# TLE985x register map
Vendor: Infineon Technologies AG; File version: 1.3
CPU: CM0 r0p0, little endian, no MPU, no FPU, 2 interrupt priority bits
Registers are 32-bit, read-write, no defined reset value unless marked. A register's access mark holds for its fields unless they carry their own. Offsets are from the block's base; [hi:lo] are bit positions; 'fields as' and 'values as' point back to an identical list.

## LIN
Base 0x4801E000
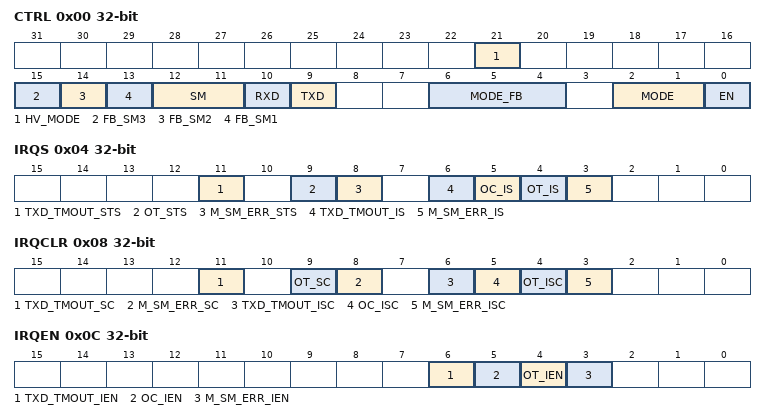
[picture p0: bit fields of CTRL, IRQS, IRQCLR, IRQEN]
0x00 CTRL access per field — LIN Transceiver Control
  [21] HV_MODE rw — LIN Transceiver High Voltage Input - Output Mode
    0=DISABLE (High Voltage Mode Entry is disabled); 1=ENABLE (High Voltage Mode Entry is enabled)
  [15] FB_SM3 ro — Feedback Signal 3 for Slope Mode Setting
  [14] FB_SM2 ro — Feedback Signal 2 for Slope Mode Setting
  [13] FB_SM1 ro — Feedback Signal 1 for Slope Mode Setting
  [12:11] SM rw — LIN Transmitter Slope mode control
    0=Normal Slope Mode (for max. 20 kBaud); 1=Fast Slope Mode (for max. 40 kBaud); 2=Low Slope Mode (for max. 10.4 kBaud); 3=Flash Mode (for max. 150 kBaud#)
  [10] RXD ro — Output Signal of Receiver
  [9] TXD rw — LIN Transmitter switch on (only used when LIN_HV_MODE is set)
    0=Pull Down LIN Line (Transmitter is switched on); 1=Pull Up Resistor is active (Transmitter is switched off)
  [6:4] MODE_FB ro — Feedback Signals for LIN Transmitter Mode Settings
  [2:1] MODE rw — LIN transceiver power mode control
    0=LIN Sleep Mode (LIN module switched to LIN Sleep Mode); 1=LIN Receive-Only Mode (LIN module switched to LIN Receive Only Mode); 3=LIN Normal Mode (LIN module switched to LIN Normal Mode)
  [0] EN rw — LIN Transceiver enable
    0=DISABLE (LIN module disable); 1=ENABLE (LIN module enable)
0x04 IRQS ro — LIN Transceiver Interrupt Status
  [11] TXD_TMOUT_STS — LIN TXD time-out Status
    0=NO_TIMEOUT (no time-out occurred); 1=TIMEOUT (time-out occurred)
  [9] OT_STS — LIN Receiver Overtemperature Status
    0=no Overtemperature (overtemperature occurred); 1=overtemperature occurred
  [8] M_SM_ERR_STS — LIN Transceiver Mode Error - Slope Mode Error Status
    0=no Mode Error - Slope Mode (status occurred); 1=Mode Error (status occurred)
  [6] TXD_TMOUT_IS — LIN TXD time-out Interrupt Status
    values as TXD_TMOUT_STS
  [5] OC_IS — LIN Receiver Overcurrent Interrupt Status
    0=no Overcurrent (overcurrent status occurred); 1=overcurrent status occurred
  [4] OT_IS — LIN Receiver Overtemperature Interrupt Status
    values as OT_STS
  [3] M_SM_ERR_IS — LIN Transceiver Mode Error - Slope Mode Error Interrupt Status
    values as M_SM_ERR_STS
0x08 IRQCLR wo — LIN Transceiver Interrupt Status Register Clear
  [11] TXD_TMOUT_SC — LIN TXD time-out Status Clear
    0=NO_Clear (no time-out cleared); 1=Clear (time-out cleared)
  [9] OT_SC — LIN Receiver Overtemperature Status Clear
    0=NO_Clear (overtemperature not cleared); 1=Clear (overtemperature cleared)
  [8] M_SM_ERR_SC — LIN Transceiver Mode Error - Slope Mode Error Status Clear
    values as OT_SC
  [6] TXD_TMOUT_ISC — LIN TXD time-out Interrupt Status Clear
    0=NO_Clear (no time-out cleared); 1=Clear (time-out cleared)
  [5] OC_ISC — LIN Receiver Overcurrent Interrupt Status Clear
    0=NO_Clear (overcurrent status not cleared); 1=Clear (overcurrent status cleared)
  [4] OT_ISC — LIN Receiver Overtemperature Interrupt Status / Status Clear
    values as OT_SC
  [3] M_SM_ERR_ISC — LIN Transceiver Mode Error - Slope Mode Error Interrupt Status Clear
    values as OT_SC
0x0C IRQEN — LIN Transceiver Interrupt Enable Register
  [all] fields
    0=disable; 1=enable
  [6] TXD_TMOUT_IEN — LIN Transceiver TxD-Timeout interrupt enable
  [5] OC_IEN — LIN Transceiver Overcurrent interrupt enable
  [4] OT_IEN — LIN Transceiver Overtemperature interrupt enable
  [3] M_SM_ERR_IEN — LIN Transceiver Mode - Slope Mode Error interrupt enable

## MATH
Base 0x48013000
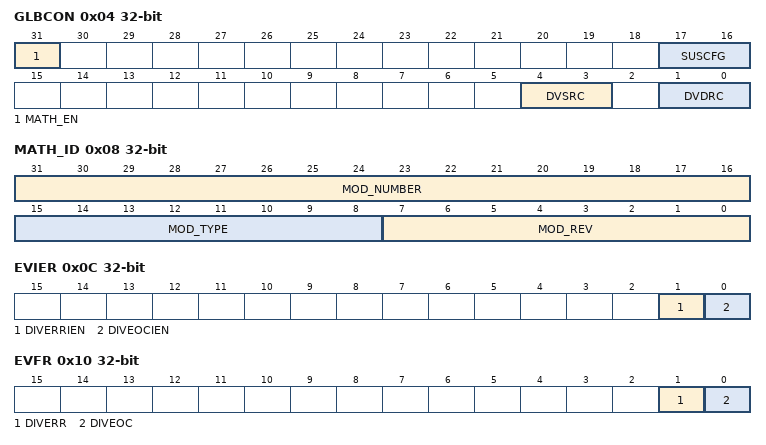
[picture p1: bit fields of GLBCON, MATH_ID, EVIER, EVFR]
0x04 GLBCON — Global Control Register
  [31] MATH_EN — Enable Math Module
    1=Enable (Math module is enabled); 0=Disable (Math module is disabled)
  [17:16] SUSCFG — Suspend Mode Configuration
    0=no suspend (Suspend mode is never entered.); 1=Hard suspend mode will be entered when CPU is halted; 2=Soft suspend mode will be entered when CPU is halted
  [4:3] DVSRC — Divisor Register Result Chaining
    0=disabled (No result chaining is selected); 1=QUOT (QUOT register is the selected source); 2=RMD (RMD register is the selected source)
  [1:0] DVDRC — Dividend Register Result Chaining
    values as DVSRC
0x08 MATH_ID ro — Module Identification Register
  [31:16] MOD_NUMBER — Module Number Value
  [15:8] MOD_TYPE — Module Type
  [7:0] MOD_REV — Module Revision Number
0x0C EVIER — Event Interupt Enable Register
  [1] DIVERRIEN — Divider Error Interrupt Enable
    0=Disable (Divider error interrupt generation is disabled); 1=Enable (Divider error interrupt generation is enabled)
  [0] DIVEOCIEN — Divider End of Calculation Interrupt Enable
    0=Disable (Divider end of calculation interrupt generation is disabled.); 1=Enable (Divider end of calculation interrupt generation is enabled.)
0x10 EVFR ro — Event Flag Register
  [1] DIVERR — Divider Error Event Flag
    0=no Error (Divider error event has not been detected); 1=Error (Divider error event has been detected)
  [0] DIVEOC — Divider End of Calculation Event Flag
    0=no EOC (Divider end of calculation event has not been detected.); 1=EOC (Divider end of calculation event has been detected.)
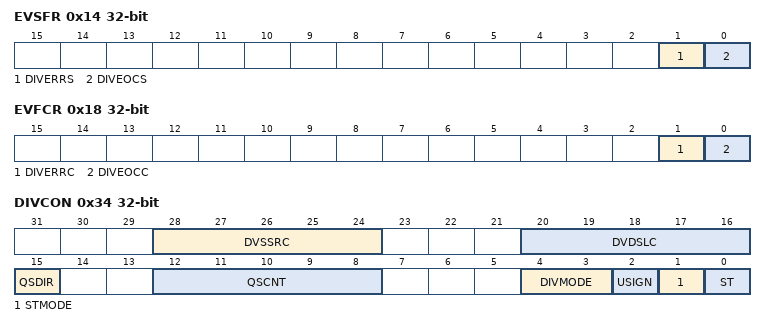
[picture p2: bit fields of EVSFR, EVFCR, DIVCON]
0x14 EVSFR wo — Event Flag Set Register
  [1] DIVERRS — Divider Error Event Flag Set
    0=no effect; 1=Set (Sets the Divider error event flag in EVFR register. Interrupt will be generated if enabled in EVIER register.)
  [0] DIVEOCS — Divider End of Calculation Event Flag Set
    0=no effect; 1=Set (Sets the Divider end of calculation event flag in EVFR register. Interrupt will be generated if enabled in EVIER register.)
0x18 EVFCR wo — Event Flag Clear Register
  [1] DIVERRC — Divider Error Event Flag Clear
    0=no effect; 1=Clears the Divider error event flag in EVFR register
  [0] DIVEOCC — Divider End of Calculation Event Flag Clear
    0=no effect; 1=Clears the Divider end of calculation event flag in EVFR register
0x20 DVD — Dividend Register
  [31:0] VAL — Dividend Value
0x24 DVS — Divisor Register
  [31:0] VAL — Divisor Value
0x28 QUOT ro — Quotient Register
  [31:0] VAL — Quotient Value
0x2C RMD ro — Remainder Register
  [31:0] VAL — Remainder Value
0x30 DIVST ro — Divider Status Register
  [0] BSY — Busy Indication
    0=finish (Divider is not running any division operation.); 1=busy (Divider is still running a division operation.)
0x34 DIVCON — Divider Control Register
  [28:24] DVSSRC — Divisor Shift Right Count
  [20:16] DVDSLC — Dividend Shift Left Count
  [15] QSDIR — Quotient Shift Direction
    0=Left shift; 1=Right Shift
  [12:8] QSCNT — Quotient Shift Count
  [4:3] DIVMODE — Division Mode
    0=32-32 (32-bit divide by 32-bit); 1=32-16 (32-bit divide by 16-bit); 2=16-16 (16-bit divide by 16-bit)
  [2] USIGN — Unsigned Division Enable
    0=Signed division is selected; 1=Unsigned division is selected
  [1] STMODE — Start Mode
    0=Auto (Calculation is automatically started with a write to DVS register); 1=Manual (Calculation is started by setting the ST bit to 1)
  [0] ST — Start Bit
    0=no effect; 1=Start the division operation when STMODE=1#
